# ATSAMV70N19 register map
Vendor: Microchip Technology; File version: 0
CPU: CM7 r1p1, little endian, no MPU, no FPU, 0x3 interrupt priority bits, 0x0 interrupts
Registers are 32-bit, read-write, reset 0x0 unless marked. A register's access mark holds for its fields unless they carry their own. Offsets are from the block's base; [hi:lo] are bit positions; {n}, {i} and the like mark numbered series.

## RSTC — Reset Controller
Base 0x400E1800; register names take the prefix RSTC_
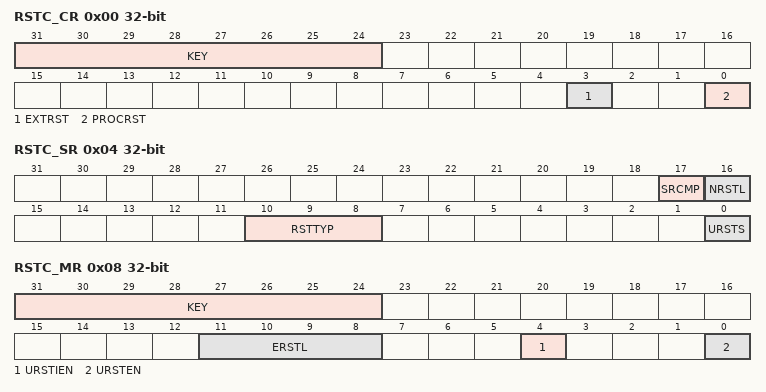
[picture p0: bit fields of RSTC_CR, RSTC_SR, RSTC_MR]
0x00 RSTC_CR wo — Control Register
  [31:24] KEY — System Reset Key
    165=PASSWD (Writing any other value in this field aborts the write operation.)
  [3] EXTRST — External Reset
  [0] PROCRST — Processor Reset
0x04 RSTC_SR ro — Status Register
  [17] SRCMP — Software Reset Command in Progress
  [16] NRSTL — NRST Pin Level
  [10:8] RSTTYP — Reset Type
    0=GENERAL_RST (First powerup reset); 1=BACKUP_RST (Return from Backup mode); 2=WDT_RST (Watchdog fault occurred); 3=SOFT_RST (Processor reset required by the software); 4=USER_RST (NRST pin detected low)
  [0] URSTS — User Reset Status
0x08 RSTC_MR — Mode Register
  [31:24] KEY — Write Access Password
    165=PASSWD (Writing any other value in this field aborts the write operation.Always reads as 0.)
  [11:8] ERSTL — External Reset Length
  [4] URSTIEN — User Reset Interrupt Enable
  [0] URSTEN — User Reset Enable

## RSWDT — Reinforced Safety Watchdog Timer
Base 0x400E1900; register names take the prefix RSWDT_
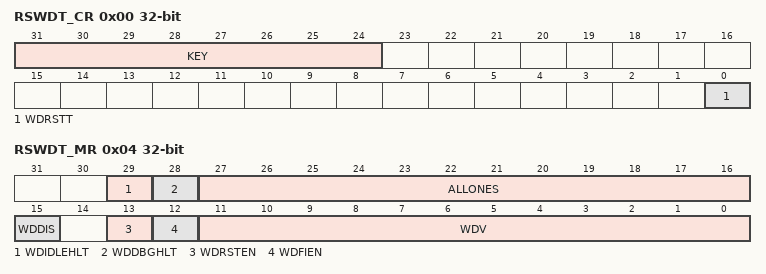
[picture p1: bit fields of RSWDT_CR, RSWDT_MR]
0x00 RSWDT_CR wo — Control Register
  [31:24] KEY — Password
    196=PASSWD (Writing any other value in this field aborts the write operation.)
  [0] WDRSTT — Watchdog Restart
0x04 RSWDT_MR — Mode Register
  [29] WDIDLEHLT — Watchdog Idle Halt
  [28] WDDBGHLT — Watchdog Debug Halt
  [27:16] ALLONES — Must Always Be Written with 0xFFF
  [15] WDDIS — Watchdog Disable
  [13] WDRSTEN — Watchdog Reset Enable
  [12] WDFIEN — Watchdog Fault Interrupt Enable
  [11:0] WDV — Watchdog Counter Value
0x08 RSWDT_SR ro — Status Register
  [0] WDUNF — Watchdog Underflow

## RTT — Real-time Timer
Base 0x400E1830; register names take the prefix RTT_
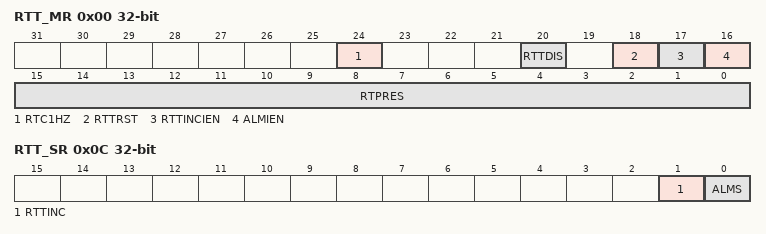
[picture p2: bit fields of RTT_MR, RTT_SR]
0x00 RTT_MR — Mode Register
  [24] RTC1HZ — Real-Time Clock 1Hz Clock Selection
  [20] RTTDIS — Real-time Timer Disable
  [18] RTTRST — Real-time Timer Restart
  [17] RTTINCIEN — Real-time Timer Increment Interrupt Enable
  [16] ALMIEN — Alarm Interrupt Enable
  [15:0] RTPRES — Real-time Timer Prescaler Value
0x04 RTT_AR — Alarm Register
  [31:0] ALMV — Alarm Value
0x08 RTT_VR ro — Value Register
  [31:0] CRTV — Current Real-time Value
0x0C RTT_SR ro — Status Register
  [1] RTTINC — Prescaler Roll-over Status (cleared on read)
  [0] ALMS — Real-time Alarm Status (cleared on read)

## SPI0 — Serial Peripheral Interface
Base 0x40008000; register names take the prefix SPI_
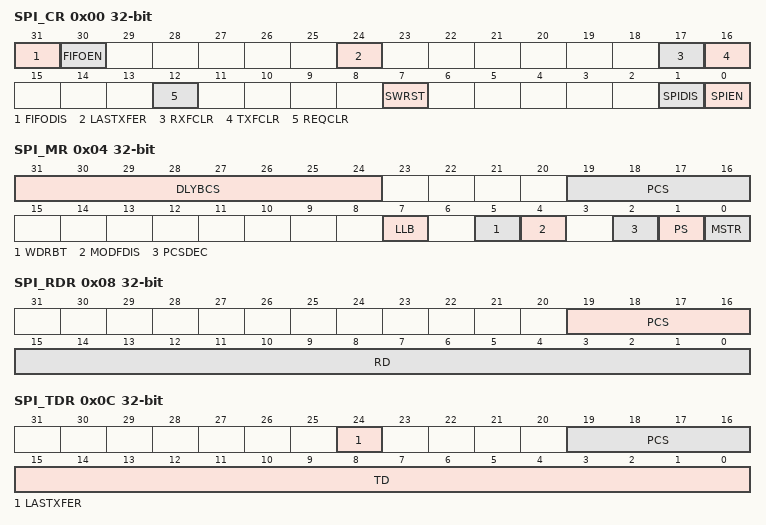
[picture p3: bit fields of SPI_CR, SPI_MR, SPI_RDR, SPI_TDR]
0x00 SPI_CR wo — Control Register
  [31] FIFODIS — FIFO Disable
  [30] FIFOEN — FIFO Enable
  [24] LASTXFER — Last Transfer
  [17] RXFCLR — Receive FIFO Clear
  [16] TXFCLR — Transmit FIFO Clear
  [12] REQCLR — Request to Clear the Comparison Trigger
  [7] SWRST — SPI Software Reset
  [1] SPIDIS — SPI Disable
  [0] SPIEN — SPI Enable
0x04 SPI_MR — Mode Register
  [31:24] DLYBCS — Delay Between Chip Selects
  [19:16] PCS — Peripheral Chip Select
  [7] LLB — Local Loopback Enable
  [5] WDRBT — Wait Data Read Before Transfer
  [4] MODFDIS — Mode Fault Detection
  [2] PCSDEC — Chip Select Decode
  [1] PS — Peripheral Select
  [0] MSTR — Master/Slave Mode
0x08 SPI_RDR ro — Receive Data Register
  [19:16] PCS — Peripheral Chip Select
  [15:0] RD — Receive Data
0x0C SPI_TDR wo — Transmit Data Register
  [24] LASTXFER — Last Transfer
  [19:16] PCS — Peripheral Chip Select
  [15:0] TD — Transmit Data
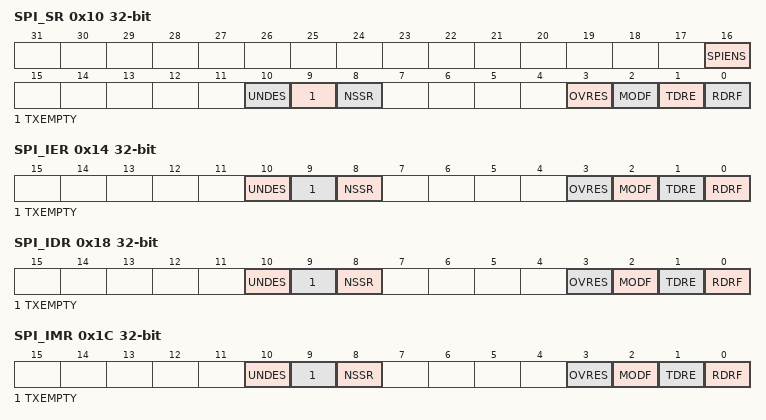
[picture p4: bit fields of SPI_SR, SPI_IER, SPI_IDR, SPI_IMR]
0x10 SPI_SR ro — Status Register
  [16] SPIENS — SPI Enable Status
  [10] UNDES — Underrun Error Status (Slave mode only) (cleared on read)
  [9] TXEMPTY — Transmission Registers Empty (cleared by writing SPI_TDR)
  [8] NSSR — NSS Rising (cleared on read)
  [3] OVRES — Overrun Error Status (cleared on read)
  [2] MODF — Mode Fault Error (cleared on read)
  [1] TDRE — Transmit Data Register Empty (cleared by writing SPI_TDR)
  [0] RDRF — Receive Data Register Full (cleared by reading SPI_RDR)
0x14 SPI_IER wo — Interrupt Enable Register
  [10] UNDES — Underrun Error Interrupt Enable
  [9] TXEMPTY — Transmission Registers Empty Enable
  [8] NSSR — NSS Rising Interrupt Enable
  [3] OVRES — Overrun Error Interrupt Enable
  [2] MODF — Mode Fault Error Interrupt Enable
  [1] TDRE — SPI Transmit Data Register Empty Interrupt Enable
  [0] RDRF — Receive Data Register Full Interrupt Enable
0x18 SPI_IDR wo — Interrupt Disable Register
  [10] UNDES — Underrun Error Interrupt Disable
  [9] TXEMPTY — Transmission Registers Empty Disable
  [8] NSSR — NSS Rising Interrupt Disable
  [3] OVRES — Overrun Error Interrupt Disable
  [2] MODF — Mode Fault Error Interrupt Disable
  [1] TDRE — SPI Transmit Data Register Empty Interrupt Disable
  [0] RDRF — Receive Data Register Full Interrupt Disable
0x1C SPI_IMR ro — Interrupt Mask Register
  [10] UNDES — Underrun Error Interrupt Mask
  [9] TXEMPTY — Transmission Registers Empty Mask
  [8] NSSR — NSS Rising Interrupt Mask
  [3] OVRES — Overrun Error Interrupt Mask
  [2] MODF — Mode Fault Error Interrupt Mask
  [1] TDRE — SPI Transmit Data Register Empty Interrupt Mask
  [0] RDRF — Receive Data Register Full Interrupt Mask
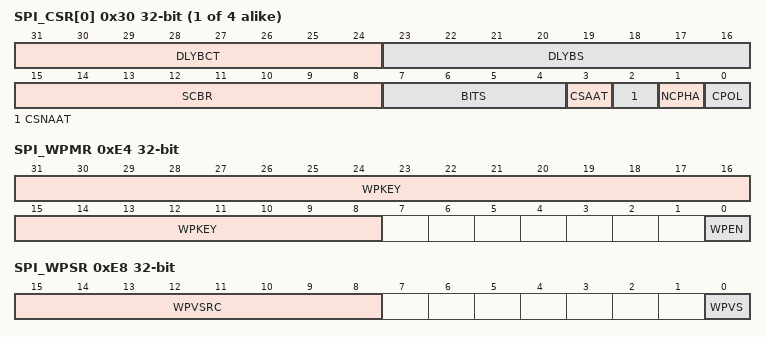
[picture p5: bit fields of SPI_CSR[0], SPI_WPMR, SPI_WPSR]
{0x30+4i} SPI_CSR[{i}] (i=0..3) — Chip Select Register (CS_number = 0) 0
  [31:24] DLYBCT — Delay Between Consecutive Transfers
  [23:16] DLYBS — Delay Before SPCK
  [15:8] SCBR — Serial Clock Bit Rate
  [7:4] BITS — Bits Per Transfer
    {v}=_{v+8}_BIT ({v+8} bits for transfer) (v=0..8)
  [3] CSAAT — Chip Select Active After Transfer
  [2] CSNAAT — Chip Select Not Active After Transfer (Ignored if CSAAT = 1)
  [1] NCPHA — Clock Phase
  [0] CPOL — Clock Polarity
0xE4 SPI_WPMR — Write Protection Mode Register
  [31:8] WPKEY — Write Protection Key
    0x535049=PASSWD (Writing any other value in this field aborts the write operation of the WPEN bit.Always reads as 0.)
  [0] WPEN — Write Protection Enable
0xE8 SPI_WPSR ro — Write Protection Status Register
  [15:8] WPVSRC — Write Protection Violation Source
  [0] WPVS — Write Protection Violation Status
